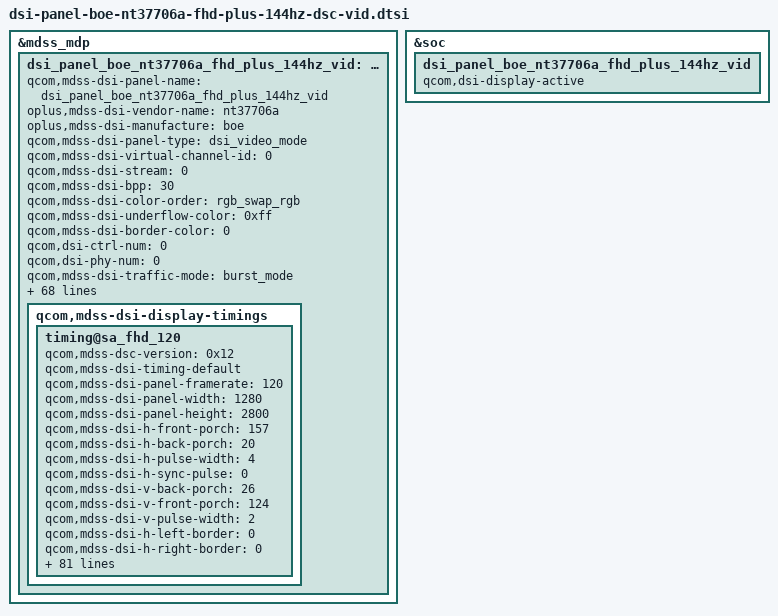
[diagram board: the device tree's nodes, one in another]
&mdss_mdp {
	dsi_panel_boe_nt37706a_fhd_plus_144hz_vid: qcom,mdss_dsi_panel_boe_nt37706a_fhd_plus_144hz_vid {
		qcom,mdss-dsi-panel-name = "dsi_panel_boe_nt37706a_fhd_plus_144hz_vid";
		oplus,mdss-dsi-vendor-name = "nt37706a";
		oplus,mdss-dsi-manufacture = "boe";
		qcom,mdss-dsi-panel-type = "dsi_video_mode";
		qcom,mdss-dsi-virtual-channel-id = <0>;
		qcom,mdss-dsi-stream = <0>;
		qcom,mdss-dsi-bpp = <30>;
		qcom,mdss-dsi-color-order = "rgb_swap_rgb";
		qcom,mdss-dsi-underflow-color = <0xff>;
		qcom,mdss-dsi-border-color = <0>;
		qcom,dsi-ctrl-num = <0>;
		qcom,dsi-phy-num = <0>;
		qcom,mdss-dsi-traffic-mode = "burst_mode";
		qcom,mdss-dsi-lane-map = "lane_map_0123";
		qcom,mdss-dsi-bllp-eof-power-mode;
		qcom,mdss-dsi-bllp-power-mode;
		qcom,mdss-dsi-lane-0-state;
		qcom,mdss-dsi-lane-1-state;
		qcom,mdss-dsi-lane-2-state;
		qcom,mdss-dsi-lane-3-state;
		qcom,mdss-dsi-dma-trigger = "trigger_sw";
		qcom,mdss-dsi-dma-schedule-line = <1>;
		qcom,mdss-dsi-dma-schedule-window = <10>;
		qcom,mdss-dsi-mdp-trigger = "none";
		qcom,mdss-dsi-reset-sequence = <1 2>, <0 5>, <1 25>;
		qcom,mdss-dsi-te-pin-select = <1>;
		qcom,mdss-dsi-te-dcs-command = <1>;
		qcom,mdss-pan-physical-width-dimension = <71>;
		qcom,mdss-pan-physical-height-dimension = <157>;
		qcom,mdss-dsi-init-delay-us = <1000>;
		qcom,mdss-dsi-te-check-enable;
		qcom,mdss-dsi-te-using-te-pin;
		//qcom,mdss-dsi-lp11-init;
		//qcom,mdss-dsi-wr-mem-start = <0x2c>;
		//qcom,mdss-dsi-wr-mem-continue = <0x3c>;
		qcom,mdss-dsi-panel-jitter = <0x4 0x1>;
		qcom,mdss-bl-high2bit;
		/* HDR Setting */
		//qcom,mdss-dsi-panel-hdr-enabled;
		qcom,mdss-dsi-panel-hdr-color-primaries = <15635 16450 34000 16000 13250 34500 7500 3000>;
		qcom,mdss-dsi-panel-peak-brightness = <30000000>;
		qcom,mdss-dsi-panel-average-brightness = <2000000>;
		qcom,mdss-dsi-panel-blackness-level = <4000>;
#if 0
		qcom,esd-check-enabled;
		oplus,esd-check-flag-enabled;
		qcom,mdss-dsi-panel-status-check-mode = "reg_read";
		qcom,mdss-dsi-panel-status-command = [
				06 00 00 00 00 00 01 0A
			];
		qcom,mdss-dsi-panel-status-command-state = "dsi_lp_mode";
		qcom,mdss-dsi-panel-status-value = <0x9C>;
		qcom,mdss-dsi-panel-status-read-length = <1>;
#endif
		qcom,mdss-dsi-display-timings {
			timing@sa_fhd_120 {
				#include "dsi-panel-boe-nt37706a-fhd-plus-144hz-dsc-vid-common.dtsi"
				//qcom,mdss-mdp-transfer-time-us = <6290>;
				//qcom,mdss-dsi-panel-jitter = <0x4 0x1>;
				qcom,mdss-dsc-version = <0x12>;
				qcom,mdss-dsi-timing-default;
				qcom,mdss-dsi-panel-framerate = <120>;
				//qcom,mdss-dsi-panel-clockrate = <1292000000>;

				qcom,mdss-dsi-panel-width = <1280>;
				qcom,mdss-dsi-panel-height = <2800>;
				qcom,mdss-dsi-h-front-porch = <157>;
				qcom,mdss-dsi-h-back-porch = <20>;
				qcom,mdss-dsi-h-pulse-width = <4>;
				qcom,mdss-dsi-h-sync-pulse = <0>;
				qcom,mdss-dsi-v-back-porch = <26>;
				qcom,mdss-dsi-v-front-porch = <124>;
				qcom,mdss-dsi-v-pulse-width = <2>;

				qcom,mdss-dsi-h-left-border = <0>;
				qcom,mdss-dsi-h-right-border = <0>;
				qcom,mdss-dsi-v-top-border = <0>;
				qcom,mdss-dsi-v-bottom-border = <0>;

				/* standard adfr */
				//qcom,mdss-dsi-h-sync-skew = <0>;
				//oplus,adfr-min-fps-mapping-table = <120 60 30 20 10 5 1>;

				// oplus,ofp-need-to-sync-data-in-aod-unlocking;
				// oplus,ofp-aod-off-insert-black-frame = <1>;
				// oplus,ofp-aod-off-black-frame-total-time = <42>;
				// oplus,ofp-need-to-separate-backlight;
				// oplus,ofp-backlight-on-period = <1>;

				qcom,mdss-dsi-panel-id1-command = [

				];

				/*qcom,mdss-dsi-pwm-timing-switch-l2-command = [
						39 00 00 40 00 00 04 FF 5A A5 00
						15 00 00 40 00 00 02 60 00
						39 00 00 40 00 00 04 FF 5A A5 2D
						39 00 00 40 00 00 03 83 00 00
						15 00 00 40 00 00 02 F2 00
						39 00 00 00 00 00 04 FF 5A A5 00
				];*/

				/*qcom,mdss-dsi-pwm-timing-switch-l1-command = [
                                                39 00 00 40 00 00 04 FF 5A A5 00
                                                15 00 00 40 00 00 02 60 01
                                                39 00 00 40 00 00 04 FF 5A A5 2D
                                                39 00 00 40 00 00 03 84 00 00
                                                15 00 00 40 00 00 02 F2 00
                                                39 00 00 00 00 00 04 FF 5A A5 00
                                ];*/

				/*qcom,mdss-dsi-pwm-timing-switch-l3-command = [
                                                39 00 00 40 00 00 04 FF 5A A5 00
                                                15 00 00 40 00 00 02 60 00
                                                39 00 00 40 00 00 04 FF 5A A5 2D
                                                39 00 00 40 00 00 03 83 00 00
                                                15 00 00 40 00 00 02 F2 00
                                                39 00 00 00 00 00 04 FF 5A A5 00
                                ];*/


				qcom,mdss-dsi-on-command = [
						39 00 00 40 00 00 03 81 01 19
						39 00 00 40 00 00 05 FF AA 55 A5 80 
						15 00 00 40 00 00 02 6F 1F
						15 00 00 40 00 00 02 F4 0B 
						15 00 00 40 00 00 02 6F 20
						15 00 00 40 00 00 02 F4 3F 
						15 00 00 40 00 00 02 6F 08
						15 00 00 40 00 00 02 FC 03
						39 00 00 40 00 00 05 FF AA 55 A5 80
						15 00 00 40 00 00 02 6F 24 
						15 00 00 40 00 00 02 F8 FF
						39 00 00 40 00 00 06 F0 55 AA 52 08 00
						15 00 00 40 00 00 02 C0 00
						39 00 00 40 00 00 06 F0 55 AA 52 08 01
						15 00 00 40 00 00 02 6F 0B
						15 00 00 40 00 00 02 D2 00
						39 00 00 40 00 00 05 FF AA 55 A5 84
						15 00 00 40 00 00 02 6F 10
						15 00 00 40 00 00 02 F8 02
						39 00 00 40 00 00 05 FF AA 55 A5 80
						15 00 00 40 00 00 02 6F 0F
						39 00 00 40 00 00 03 F8 01 FF
						39 00 00 40 00 00 06 F0 55 AA 52 08 09
						15 00 00 40 00 00 02 6F 00
						15 00 00 40 00 00 02 B0 01
						15 00 00 40 00 00 02 87 00
						15 00 00 40 00 00 02 6F 01
						15 00 00 40 00 00 02 8B 00
						39 00 00 40 00 00 05 2A 00 00 04 FF
						39 00 00 40 00 00 05 2B 00 00 0A EF
						15 00 00 40 00 00 02 17 03
						15 00 00 40 00 00 02 90 03
						15 00 00 40 00 00 02 6F 01
						15 00 00 40 00 00 02 90 43
						39 00 00 40 00 00 13 91 AB A8 00 28 C2 00 02 41 04 33 00 08 02 77 02 20 10 E0
						15 00 00 40 00 00 02 53 20
						39 00 00 40 00 00 11 3B 00 1c 00 74 00 1c 00 7C 00 1c 04 54 00 1c 00 7C
						15 00 00 40 00 00 02 6F 10
						39 00 00 40 00 00 05 3B 00 1C 00 7C
						15 00 00 40 00 00 02 88 01
						15 00 00 40 00 00 02 2F 01
						15 00 00 40 00 00 02 35 00
						39 00 00 40 00 00 03 5F 00 00
						39 00 00 00 00 00 03 51 0D BB
						15 00 00 00 78 00 02 11 00
						15 00 00 00 14 00 02 29 00
				];

				qcom,mdss-dsi-adfr-auto-on-command = [
					/* SDC Auto On */
				];
				qcom,mdss-dsi-adfr-auto-off-command = [
					/* SDC Auto Off */
				];

				qcom,mdss-dsi-post-on-backlight = [

				];

				qcom,mdss-dsi-panel-read-register-open-command = [
				];
				qcom,mdss-dsi-panel-read-register-close-command = [
				];

				qcom,mdss-dsi-temperature-compensation-command = [
				];
				qcom,mdss-dsi-read-compensation-reg1-command = [
				];

				qcom,mdss-dsi-vid-144hz-switch-command = [
					15 00 00 00 00 00 02 2F 00
				];
				qcom,mdss-dsi-vid-120hz-switch-command = [
					15 00 00 00 00 00 02 2F 01
				];
				qcom,mdss-dsi-vid-90hz-switch-command = [
					15 00 00 10 00 00 02 2F 02
				];
				qcom,mdss-dsi-vid-60hz-switch-command = [
					15 00 00 10 00 00 02 2F 03
				];

				qcom,mdss-dsi-on-command-state = "dsi_lp_mode";
				qcom,mdss-dsi-on-high-fre-command-state = "dsi_lp_mode";
				qcom,mdss-dsi-nolp-hpwm-command-state = "dsi_lp_sync1_mode";
				qcom,mdss-dsi-panel-read-register-open-state = "dsi_lp_mode";
				qcom,mdss-dsi-panel-read-register-close-state = "dsi_lp_mode";
				qcom,mdss-dsi-reset-scanline-command-state = "dsi_hs_mode";
				qcom,mdss-dsi-recovery-scanline-command-state = "dsi_hs_mode";

				qcom,mdss-dsi-adfr-auto-on-command-state ="dsi_hs_mode";
				qcom,mdss-dsi-adfr-auto-off-command-state ="dsi_hs_mode";
				qcom,mdss-dsi-temperature-compensation-command-state = "dsi_hs_mode";
				qcom,mdss-dsi-read-compensation-reg1-command-state = "dsi_hs_mode";
				qcom,mdss-dsi-osc-track-on-command-state = "dsi_hs_mode";
				qcom,mdss-dsi-osc-track-off-command-state = "dsi_hs_mode";

				qcom,mdss-dsi-pwm-timing-switch-l1-command-state = "dsi_hs_mode";
				qcom,mdss-dsi-pwm-timing-switch-l2-command-state = "dsi_hs_mode";
				qcom,mdss-dsi-pwm-timing-switch-l3-command-state = "dsi_hs_mode";
				qcom,mdss-dsi-pwm-switch-mode0-command-state = "dsi_hs_mode";
				qcom,mdss-dsi-pwm-switch-mode1-command-state = "dsi_hs_mode";

				qcom,mdss-dsi-vid-144hz-switch-command-state = "dsi_lp_mode";
				qcom,mdss-dsi-vid-120hz-switch-command-state = "dsi_lp_mode";
				qcom,mdss-dsi-vid-90hz-switch-command-state = "dsi_lp_mode";
				qcom,mdss-dsi-vid-60hz-switch-command-state = "dsi_lp_mode";

				qcom,compression-mode = "dsc";
				qcom,mdss-dsc-encoders = <2>;
				qcom,mdss-dsc-slice-height = <40>;
				qcom,mdss-dsc-slice-width = <640>;
				qcom,mdss-dsc-slice-per-pkt = <2>;
				qcom,mdss-dsc-bit-per-component = <8>;
				qcom,mdss-dsc-bit-per-pixel = <8>;
				qcom,mdss-dsc-block-prediction-enable;
				qcom,mdss-dsi-panel-id1-command-state = "dsi_lp_mode";
			};
		};
	};
};

&soc {
	dsi_panel_boe_nt37706a_fhd_plus_144hz_vid {
		qcom,dsi-display-active;
	};
};

&dsi_panel_boe_nt37706a_fhd_plus_144hz_vid {
	qcom,panel-supply-entries = <&oplus_dsi_panel_custom_pwr_supply>;
	qcom,mdss-dsi-panel-controller = <&mdss_dsi0>;
	qcom,mdss-dsi-bl-pmic-control-type = "bl_ctrl_dcs";
	qcom,bl-update-flag = "delay_until_first_frame";
	qcom,mdss-dsi-bl-min-level = <1>;
	qcom,mdss-dsi-bl-max-level = <4095>;
	qcom,mdss-brightness-max-level = <4095>;
	oplus,dsi-bl-normal-max-level = <3626>;
	oplus,dsi-brightness-normal-max-level = <3626>;
	oplus,dsi-dc-backlight-threshold = <1960>;
	oplus,dsi-brightness-default-level = <1638>;
	qcom,platform-te-gpio = <&tlmm 17 0>;
	qcom,platform-reset-gpio = <&tlmm 12 0>;

	oplus,panel-reset-position = <0x02>;
	oplus,panel-power-on-sequence = "10", "vddio", "10", "vdd", "10", "vci", "10";
	oplus,panel-power-off-sequence = "10", "vci", "10", "vdd", "10", "vddio", "10";

	qcom,mdss-dsi-bl-inverted-dbv;
	qcom,ulps-enabled;
	qcom,dsi-select-clocks = "pll_byte_clk0", "pll_dsi_clk0";
	/* ofp config */
	//oplus,ofp-fp-type = <0x90>;
	//oplus,ofp-need-to-wait-data-before-aod-on;

	/* adfr config */
	/* just for qsync enable*/
	//qcom,qsync-enable;
	//qcom,mdss-dsi-qsync-min-refresh-rate = <24>;
	/*
	** 0st bit: adfr global on/off
	** 1st bit: fakeframe on/off
	** 2st bit: switch on/off
	** 3rd bit: 0:double-TE switch 1:external TE/TP switch
	** 4rd bit: idle mode on/off
	** 5th bit: temperature compensation mode on/off
	*/
	/*
	 oplus,adfr-config = <0x1051>;  // 0b1110'0101'0001
	 oplus,adfr-test-te-gpio = <&tlmm 85 0>;
	 */

	/* fps-switch */
	/*qcom,mdss-dsi-pan-enable-dynamic-fps;
	qcom,mdss-dsi-pan-fps-update = "dfps_immediate_porch_mode_custom";
	qcom,dsi-supported-dfps-list = <144 120 90 60>;
	qcom,dsi-dfps-hbp-list = <20 20 20 20>;
	qcom,dsi-dfps-hfp-list = <57 157 157 157>;
	qcom,dsi-dfps-hpw-list = <4 4 4 4>;
	qcom,dsi-dfps-vbp-list = <26 26 26 26>;
	qcom,dsi-dfps-vfp-list = <116 124 1108 3076>;
	qcom,dsi-dfps-vpw-list = <2 2 2 2>;
	qcom,mdss-dsi-min-refresh-rate = <60>;
	qcom,mdss-dsi-max-refresh-rate = <144>;*/

	/* vid-timming-switch */
	//oplus,dsi-vid-timming-switch_enable;
	//oplus,dsi-vidmode-backlight-async-wait-enable;
	//oplus,dsi-set-backlight-not-do-esd-reg-read-enable;

	qcom,mdss-dsi-display-timings {
		timing@sa_fhd_120 { /* FHD+ 120hz 1292Mbps */
			qcom,mdss-dsi-panel-phy-timings = [00 2A 0B 0B 1C 1A 0B 0C 0B 02 04 00 23 10];
			qcom,display-topology = <1 1 1>,<2 2 1>;
			qcom,default-topology-index = <1>;
			//qcom,dsi-dyn-clk-list = <1112000000 1056000000>;
		};
	};
};
&dsi_panel_boe_nt37706a_fhd_plus_144hz_vid {
	qcom,panel_voltage_vddi_name = "vddio";
	qcom,panel_voltage_vddi = <0 1800000 1850000 1950000>;
 	qcom,panel_voltage_vddr_name = "vdd";
	qcom,panel_voltage_vddr = <1 1200000 1200000 1200000>;
 	qcom,panel_voltage_vci_name = "vci";
 	qcom,panel_voltage_vci = <1 3000000 3200000 3300000>;
};

&dsi_panel_boe_nt37706a_fhd_plus_144hz_vid{
	oplus,color_vivid_status;
	oplus,color_srgb_status;
	//oplus,color_softiris_status;
	oplus,color_dual_brightness_status;
	oplus,color_2nit_status;
	oplus,color_oplus_calibrate_status;
	oplus,color_samsung_status;
	oplus,color_loading_status;
	//oplus,color_nature_profession_status;
	oplus,mdss-dsi-panel-type = <0>;

	/* serial num config */
	/*
	oplus,dsi-serial-number-enabled;
	oplus,dsi-serial-number-switch-page;
	oplus,dsi-serial-number-index= <0x0>;
	oplus,dsi-serial-number-reg= <0x82>;
	oplus,dsi-serial-number-read-count= <7>;
	*/

	/* demura dbv config */
	//oplus,bl_denura-dbv-switch-support;

	/*Feature config*/
	//oplus,pwm-switch-support;
	//oplus,pwm-switch-restore-support;
	//oplus,pwm-switch-backlight-threshold = <1087>;
	//oplus,pwm-create-thread-disable-duty;
	//oplus,cmdq-pack-support;
	//oplus,dp-enabled;
};

&dsi_panel_boe_nt37706a_fhd_plus_144hz_vid {
	/* demura dbv config */
	/* pwm config */
	/*	oplus,pwm-switch-config:
		Bit0: pwm feature enable
		Bit1: pwm mode switch enable, need to config switch cmds
		Bit2: force enabled pwm mode switch cmd, will send mode cmd even dbv threshold cmd feature is configed
		Bit3: pwm dbv threshold pulse switch enable, need to config threshold switch cmds
		Bit4: wait te before sending pwm dbv threshold pulse switch cmd
		Bit5: replace specific cmd to other cmd while in pwm 1pulse mode
		Bit6: sending extend cmd while panel power on accroding to current pwm mode
		Bit7: sending extend cmd while timing switch accroding to current pwm pulse level
		Bit8: sending extend cmd after sending dbv threshold cmd in another thread
	*/
	//oplus,pwm-switch-config = <0x87>;
	/*	oplus,pwm-switch-mode0-states-info/oplus,pwm-switch-mode1-states-info:
		Specific dbv threshold and pulse info of 2 pwm mode, for pulse, 0 symbols 1pulse,
		1symbols 3pulse and 2 symbols 18pulse. The format should be 1 dbv threshold info with
		2 pwm pulse levels left and right(for example, <2 1087 1> means 18pulse while dbv <= 1087
		and 3pulse while dbv > 1087), or only one pulse level, no threshold.
	*/
	//oplus,pwm-switch-mode0-states-info = <2 1162 1>;
	//oplus,pwm-switch-mode1-states-info = <2 1162 0>;
};
